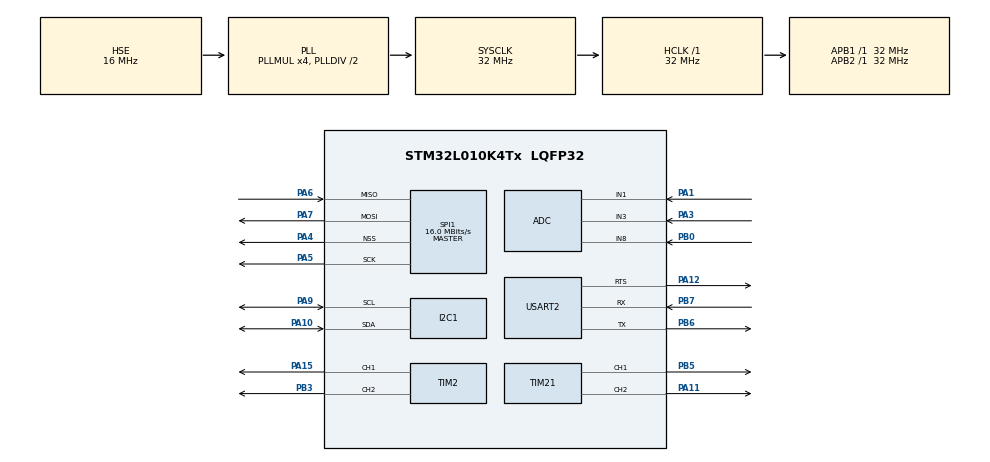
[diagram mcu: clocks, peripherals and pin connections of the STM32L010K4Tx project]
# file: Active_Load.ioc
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Dma.Request0=TIM2_CH1
Dma.Request1=TIM2_CH2
Dma.TIM2_CH1.0.Direction=DMA_MEMORY_TO_PERIPH
Dma.TIM2_CH1.0.Instance=DMA1_Channel5
Dma.TIM2_CH1.0.MemDataAlignment=DMA_MDATAALIGN_HALFWORD
Dma.TIM2_CH1.0.MemInc=DMA_MINC_ENABLE
Dma.TIM2_CH1.0.Mode=DMA_NORMAL
Dma.TIM2_CH1.0.PeriphDataAlignment=DMA_PDATAALIGN_HALFWORD
Dma.TIM2_CH1.0.PeriphInc=DMA_PINC_DISABLE
Dma.TIM2_CH1.0.Priority=DMA_PRIORITY_HIGH
Dma.TIM2_CH2.1.Direction=DMA_MEMORY_TO_PERIPH
Dma.TIM2_CH2.1.Instance=DMA1_Channel3
Dma.TIM2_CH2.1.MemDataAlignment=DMA_MDATAALIGN_HALFWORD
Dma.TIM2_CH2.1.MemInc=DMA_MINC_ENABLE
Dma.TIM2_CH2.1.Mode=DMA_NORMAL
Dma.TIM2_CH2.1.PeriphDataAlignment=DMA_PDATAALIGN_HALFWORD
Dma.TIM2_CH2.1.PeriphInc=DMA_PINC_DISABLE
Dma.TIM2_CH2.1.Priority=DMA_PRIORITY_HIGH
I2C1.Timing=0x00707CBB
Mcu.Family=STM32L0
Mcu.Name=STM32L010K4Tx
Mcu.Package=LQFP32
NVIC.DMA1_Channel2_3_IRQn=true\:0\:0\:false\:false\:true\:false\:true\:true
NVIC.DMA1_Channel4_5_IRQn=true\:0\:0\:false\:false\:true\:false\:true\:true
PA0-CK_IN.Mode=HSE-External-Clock-Source-for-TinyNemo
PA0-CK_IN.Signal=RCC_CK_IN
PA1.Mode=IN1
PA1.Signal=ADC_IN1
PA10.Mode=I2C
PA10.Signal=I2C1_SDA
PA11.Signal=S_TIM21_CH2
PA12.Mode=RTS_Only
PA12.Signal=USART2_RTS
PA13.Mode=Serial_Wire
PA13.Signal=SYS_SWDIO
PA14.Mode=Serial_Wire
PA14.Signal=SYS_SWCLK
PA15.Signal=S_TIM2_CH1
PA2.Mode=SYS_WakeUp2
PA2.Signal=SYS_WKUP3
PA3.Mode=IN3
PA3.Signal=ADC_IN3
PA4.Mode=NSS_Signal_Hard_Output
PA4.Signal=SPI1_NSS
PA5.Mode=Full_Duplex_Master
PA5.Signal=SPI1_SCK
PA6.Mode=Full_Duplex_Master
PA6.Signal=SPI1_MISO
PA7.Mode=Full_Duplex_Master
PA7.Signal=SPI1_MOSI
PA9.Mode=I2C
PA9.Signal=I2C1_SCL
PB0.Mode=IN8
PB0.Signal=ADC_IN8
PB1.Mode=VREFINT_ADC_PB1
PB1.Signal=SYS_VREF_OUT_PB1
PB3.Signal=S_TIM2_CH2
PB5.Signal=S_TIM21_CH1
PB6.Mode=Asynchronous
PB6.Signal=USART2_TX
PB7.Mode=Asynchronous
PB7.Signal=USART2_RX
ProjectManager.HeapSize=0x100
ProjectManager.StackSize=0x200
ProjectManager.TargetToolchain=STM32CubeIDE
RCC.AHBFreq_Value=32000000
RCC.APB1Freq_Value=32000000
RCC.APB1TimFreq_Value=32000000
RCC.APB2Freq_Value=32000000
RCC.APB2TimFreq_Value=32000000
RCC.HCLKFreq_Value=32000000
RCC.HSE_VALUE=16000000
RCC.HSI16_VALUE=16000000
RCC.HSI_VALUE=16000000
RCC.LSE_VALUE=32768
RCC.MSI_VALUE=2097000
RCC.PLLMUL=RCC_PLLMUL_4
RCC.PLLSourceVirtual=RCC_PLLSOURCE_HSE
RCC.SYSCLKFreq_VALUE=32000000
RCC.SYSCLKSource=RCC_SYSCLKSOURCE_PLLCLK
RCC.VCOOutputFreq_Value=64000000
SH.S_TIM21_CH1.0=TIM21_CH1,PWM Generation1 CH1
SH.S_TIM21_CH2.0=TIM21_CH2,PWM Generation2 CH2
SH.S_TIM2_CH1.0=TIM2_CH1,PWM Generation1 CH1
SH.S_TIM2_CH2.0=TIM2_CH2,PWM Generation2 CH2
SPI1.CalculateBaudRate=16.0 MBits/s
SPI1.Direction=SPI_DIRECTION_2LINES
SPI1.Mode=SPI_MODE_MASTER
SPI1.VirtualNSS=VM_NSSHARD
SPI1.VirtualType=VM_MASTER
TIM2.Channel-PWM\ Generation1\ CH1=TIM_CHANNEL_1
TIM2.Channel-PWM\ Generation2\ CH2=TIM_CHANNEL_2
TIM21.Channel-PWM\ Generation1\ CH1=TIM_CHANNEL_1
TIM21.Channel-PWM\ Generation2\ CH2=TIM_CHANNEL_2
USART2.VirtualMode=VM_ASYNC
VP_TIM21_VS_ClockSourceINT.Mode=Internal
VP_TIM2_VS_ClockSourceINT.Mode=Internal
board=custom

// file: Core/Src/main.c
/* USER CODE BEGIN Header */
/**
  ******************************************************************************
  * @file           : main.c
  * @brief          : Main program body
  ******************************************************************************
  * @attention
  *
  * Copyright (c) 2022 STMicroelectronics.
  * All rights reserved.
  *
  * This software is licensed under terms that can be found in the LICENSE file
  * in the root directory of this software component.
  * If no LICENSE file comes with this software, it is provided AS-IS.
  *
  ******************************************************************************
  */
/* USER CODE END Header */
#include "main.h"

/* USER CODE BEGIN Includes */
#include "i2c-lcd.h"
/* USER CODE END Includes */

ADC_HandleTypeDef hadc;

I2C_HandleTypeDef hi2c1;

SPI_HandleTypeDef hspi1;

TIM_HandleTypeDef htim2;
TIM_HandleTypeDef htim21;
DMA_HandleTypeDef hdma_tim2_ch1;
DMA_HandleTypeDef hdma_tim2_ch2;

UART_HandleTypeDef huart2;

void SystemClock_Config(void);
static void MX_GPIO_Init(void);
static void MX_DMA_Init(void);
static void MX_ADC_Init(void);
static void MX_I2C1_Init(void);
static void MX_SPI1_Init(void);
static void MX_TIM2_Init(void);
static void MX_TIM21_Init(void);
static void MX_USART2_UART_Init(void);

int main(void)
{

  /* MCU Configuration--------------------------------------------------------*/

  /* Reset of all peripherals, Initializes the Flash interface and the Systick. */
  HAL_Init();

  /* Configure the system clock */
  SystemClock_Config();

  /* Initialize all configured peripherals */
  MX_GPIO_Init();
  MX_DMA_Init();
  MX_ADC_Init();
  MX_I2C1_Init();
  MX_SPI1_Init();
  MX_TIM2_Init();
  MX_TIM21_Init();
  MX_USART2_UART_Init();
  /* USER CODE BEGIN 2 */

  lcd_init();  //start LCD
  lcd_send_string("cava txt");
  HAL_Delay(5000);
  lcd_clear();
  lcd_put_cur(1,0);
  lcd_send_string("ceva txt22");

  /* USER CODE END 2 */

  /* Infinite loop */
  while (1)
  {

    /* USER CODE BEGIN 3 */

	  // void loop is here
  }
  /* USER CODE END 3 */
}

void SystemClock_Config(void)
{
  RCC_OscInitTypeDef RCC_OscInitStruct = {0};
  RCC_ClkInitTypeDef RCC_ClkInitStruct = {0};
  RCC_PeriphCLKInitTypeDef PeriphClkInit = {0};

  /** Configure the main internal regulator output voltage
  */
  __HAL_PWR_VOLTAGESCALING_CONFIG(PWR_REGULATOR_VOLTAGE_SCALE1);

  /** Initializes the RCC Oscillators according to the specified parameters
  * in the RCC_OscInitTypeDef structure.
  */
  RCC_OscInitStruct.OscillatorType = RCC_OSCILLATORTYPE_HSE;
  RCC_OscInitStruct.HSEState = RCC_HSE_BYPASS;
  RCC_OscInitStruct.PLL.PLLState = RCC_PLL_ON;
  RCC_OscInitStruct.PLL.PLLSource = RCC_PLLSOURCE_HSE;
  RCC_OscInitStruct.PLL.PLLMUL = RCC_PLLMUL_4;
  RCC_OscInitStruct.PLL.PLLDIV = RCC_PLLDIV_2;
  if (HAL_RCC_OscConfig(&RCC_OscInitStruct) != HAL_OK)
  {
    Error_Handler();
  }

  /** Initializes the CPU, AHB and APB buses clocks
  */
  RCC_ClkInitStruct.ClockType = RCC_CLOCKTYPE_HCLK|RCC_CLOCKTYPE_SYSCLK
                              |RCC_CLOCKTYPE_PCLK1|RCC_CLOCKTYPE_PCLK2;
  RCC_ClkInitStruct.SYSCLKSource = RCC_SYSCLKSOURCE_PLLCLK;
  RCC_ClkInitStruct.AHBCLKDivider = RCC_SYSCLK_DIV1;
  RCC_ClkInitStruct.APB1CLKDivider = RCC_HCLK_DIV1;
  RCC_ClkInitStruct.APB2CLKDivider = RCC_HCLK_DIV1;

  if (HAL_RCC_ClockConfig(&RCC_ClkInitStruct, FLASH_LATENCY_1) != HAL_OK)
  {
    Error_Handler();
  }
  PeriphClkInit.PeriphClockSelection = RCC_PERIPHCLK_USART2|RCC_PERIPHCLK_I2C1;
  PeriphClkInit.Usart2ClockSelection = RCC_USART2CLKSOURCE_PCLK1;
  PeriphClkInit.I2c1ClockSelection = RCC_I2C1CLKSOURCE_PCLK1;
  if (HAL_RCCEx_PeriphCLKConfig(&PeriphClkInit) != HAL_OK)
  {
    Error_Handler();
  }
}

static void MX_ADC_Init(void)
{

  ADC_ChannelConfTypeDef sConfig = {0};

  /** Configure the global features of the ADC (Clock, Resolution, Data Alignment and number of conversion)
  */
  hadc.Instance = ADC1;
  hadc.Init.OversamplingMode = DISABLE;
  hadc.Init.ClockPrescaler = ADC_CLOCK_SYNC_PCLK_DIV2;
  hadc.Init.Resolution = ADC_RESOLUTION_12B;
  hadc.Init.SamplingTime = ADC_SAMPLETIME_1CYCLE_5;
  hadc.Init.ScanConvMode = ADC_SCAN_DIRECTION_FORWARD;
  hadc.Init.DataAlign = ADC_DATAALIGN_RIGHT;
  hadc.Init.ContinuousConvMode = DISABLE;
  hadc.Init.DiscontinuousConvMode = DISABLE;
  hadc.Init.ExternalTrigConvEdge = ADC_EXTERNALTRIGCONVEDGE_NONE;
  hadc.Init.ExternalTrigConv = ADC_SOFTWARE_START;
  hadc.Init.DMAContinuousRequests = DISABLE;
  hadc.Init.EOCSelection = ADC_EOC_SINGLE_CONV;
  hadc.Init.Overrun = ADC_OVR_DATA_PRESERVED;
  hadc.Init.LowPowerAutoWait = DISABLE;
  hadc.Init.LowPowerFrequencyMode = DISABLE;
  hadc.Init.LowPowerAutoPowerOff = DISABLE;
  if (HAL_ADC_Init(&hadc) != HAL_OK)
  {
    Error_Handler();
  }

  /** Configure for the selected ADC regular channel to be converted.
  */
  sConfig.Channel = ADC_CHANNEL_1;
  sConfig.Rank = ADC_RANK_CHANNEL_NUMBER;
  if (HAL_ADC_ConfigChannel(&hadc, &sConfig) != HAL_OK)
  {
    Error_Handler();
  }

  /** Configure for the selected ADC regular channel to be converted.
  */
  sConfig.Channel = ADC_CHANNEL_3;
  if (HAL_ADC_ConfigChannel(&hadc, &sConfig) != HAL_OK)
  {
    Error_Handler();
  }

  /** Configure for the selected ADC regular channel to be converted.
  */
  sConfig.Channel = ADC_CHANNEL_8;
  if (HAL_ADC_ConfigChannel(&hadc, &sConfig) != HAL_OK)
  {
    Error_Handler();
  }

}

static void MX_I2C1_Init(void)
{

  hi2c1.Instance = I2C1;
  hi2c1.Init.Timing = 0x00707CBB;
  hi2c1.Init.OwnAddress1 = 0;
  hi2c1.Init.AddressingMode = I2C_ADDRESSINGMODE_7BIT;
  hi2c1.Init.DualAddressMode = I2C_DUALADDRESS_DISABLE;
  hi2c1.Init.OwnAddress2 = 0;
  hi2c1.Init.OwnAddress2Masks = I2C_OA2_NOMASK;
  hi2c1.Init.GeneralCallMode = I2C_GENERALCALL_DISABLE;
  hi2c1.Init.NoStretchMode = I2C_NOSTRETCH_DISABLE;
  if (HAL_I2C_Init(&hi2c1) != HAL_OK)
  {
    Error_Handler();
  }

  /** Configure Analogue filter
  */
  if (HAL_I2CEx_ConfigAnalogFilter(&hi2c1, I2C_ANALOGFILTER_ENABLE) != HAL_OK)
  {
    Error_Handler();
  }

  /** Configure Digital filter
  */
  if (HAL_I2CEx_ConfigDigitalFilter(&hi2c1, 0) != HAL_OK)
  {
    Error_Handler();
  }

}

static void MX_SPI1_Init(void)
{

  /* SPI1 parameter configuration*/
  hspi1.Instance = SPI1;
  hspi1.Init.Mode = SPI_MODE_MASTER;
  hspi1.Init.Direction = SPI_DIRECTION_2LINES;
  hspi1.Init.DataSize = SPI_DATASIZE_8BIT;
  hspi1.Init.CLKPolarity = SPI_POLARITY_LOW;
  hspi1.Init.CLKPhase = SPI_PHASE_1EDGE;
  hspi1.Init.NSS = SPI_NSS_HARD_OUTPUT;
  hspi1.Init.BaudRatePrescaler = SPI_BAUDRATEPRESCALER_2;
  hspi1.Init.FirstBit = SPI_FIRSTBIT_MSB;
  hspi1.Init.TIMode = SPI_TIMODE_DISABLE;
  hspi1.Init.CRCCalculation = SPI_CRCCALCULATION_DISABLE;
  hspi1.Init.CRCPolynomial = 7;
  if (HAL_SPI_Init(&hspi1) != HAL_OK)
  {
    Error_Handler();
  }

}

static void MX_TIM2_Init(void)
{

  TIM_ClockConfigTypeDef sClockSourceConfig = {0};
  TIM_MasterConfigTypeDef sMasterConfig = {0};
  TIM_OC_InitTypeDef sConfigOC = {0};

  htim2.Instance = TIM2;
  htim2.Init.Prescaler = 0;
  htim2.Init.CounterMode = TIM_COUNTERMODE_UP;
  htim2.Init.Period = 65535;
  htim2.Init.ClockDivision = TIM_CLOCKDIVISION_DIV1;
  htim2.Init.AutoReloadPreload = TIM_AUTORELOAD_PRELOAD_DISABLE;
  if (HAL_TIM_Base_Init(&htim2) != HAL_OK)
  {
    Error_Handler();
  }
  sClockSourceConfig.ClockSource = TIM_CLOCKSOURCE_INTERNAL;
  if (HAL_TIM_ConfigClockSource(&htim2, &sClockSourceConfig) != HAL_OK)
  {
    Error_Handler();
  }
  if (HAL_TIM_PWM_Init(&htim2) != HAL_OK)
  {
    Error_Handler();
  }
  sMasterConfig.MasterOutputTrigger = TIM_TRGO_RESET;
  sMasterConfig.MasterSlaveMode = TIM_MASTERSLAVEMODE_DISABLE;
  if (HAL_TIMEx_MasterConfigSynchronization(&htim2, &sMasterConfig) != HAL_OK)
  {
    Error_Handler();
  }
  sConfigOC.OCMode = TIM_OCMODE_PWM1;
  sConfigOC.Pulse = 0;
  sConfigOC.OCPolarity = TIM_OCPOLARITY_HIGH;
  sConfigOC.OCFastMode = TIM_OCFAST_DISABLE;
  if (HAL_TIM_PWM_ConfigChannel(&htim2, &sConfigOC, TIM_CHANNEL_1) != HAL_OK)
  {
    Error_Handler();
  }
  if (HAL_TIM_PWM_ConfigChannel(&htim2, &sConfigOC, TIM_CHANNEL_2) != HAL_OK)
  {
    Error_Handler();
  }
  HAL_TIM_MspPostInit(&htim2);

}

static void MX_TIM21_Init(void)
{

  TIM_ClockConfigTypeDef sClockSourceConfig = {0};
  TIM_MasterConfigTypeDef sMasterConfig = {0};
  TIM_OC_InitTypeDef sConfigOC = {0};

  htim21.Instance = TIM21;
  htim21.Init.Prescaler = 0;
  htim21.Init.CounterMode = TIM_COUNTERMODE_UP;
  htim21.Init.Period = 65535;
  htim21.Init.ClockDivision = TIM_CLOCKDIVISION_DIV1;
  htim21.Init.AutoReloadPreload = TIM_AUTORELOAD_PRELOAD_DISABLE;
  if (HAL_TIM_Base_Init(&htim21) != HAL_OK)
  {
    Error_Handler();
  }
  sClockSourceConfig.ClockSource = TIM_CLOCKSOURCE_INTERNAL;
  if (HAL_TIM_ConfigClockSource(&htim21, &sClockSourceConfig) != HAL_OK)
  {
    Error_Handler();
  }
  if (HAL_TIM_PWM_Init(&htim21) != HAL_OK)
  {
    Error_Handler();
  }
  sMasterConfig.MasterOutputTrigger = TIM_TRGO_RESET;
  sMasterConfig.MasterSlaveMode = TIM_MASTERSLAVEMODE_DISABLE;
  if (HAL_TIMEx_MasterConfigSynchronization(&htim21, &sMasterConfig) != HAL_OK)
  {
    Error_Handler();
  }
  sConfigOC.OCMode = TIM_OCMODE_PWM1;
  sConfigOC.Pulse = 0;
  sConfigOC.OCPolarity = TIM_OCPOLARITY_HIGH;
  sConfigOC.OCFastMode = TIM_OCFAST_DISABLE;
  if (HAL_TIM_PWM_ConfigChannel(&htim21, &sConfigOC, TIM_CHANNEL_1) != HAL_OK)
  {
    Error_Handler();
  }
  if (HAL_TIM_PWM_ConfigChannel(&htim21, &sConfigOC, TIM_CHANNEL_2) != HAL_OK)
  {
    Error_Handler();
  }
  HAL_TIM_MspPostInit(&htim21);

}

static void MX_USART2_UART_Init(void)
{

  huart2.Instance = USART2;
  huart2.Init.BaudRate = 115200;
  huart2.Init.WordLength = UART_WORDLENGTH_8B;
  huart2.Init.StopBits = UART_STOPBITS_1;
  huart2.Init.Parity = UART_PARITY_NONE;
  huart2.Init.Mode = UART_MODE_TX_RX;
  huart2.Init.HwFlowCtl = UART_HWCONTROL_RTS;
  huart2.Init.OverSampling = UART_OVERSAMPLING_16;
  huart2.Init.OneBitSampling = UART_ONE_BIT_SAMPLE_DISABLE;
  huart2.AdvancedInit.AdvFeatureInit = UART_ADVFEATURE_NO_INIT;
  if (HAL_UART_Init(&huart2) != HAL_OK)
  {
    Error_Handler();
  }

}

static void MX_DMA_Init(void)
{

  /* DMA controller clock enable */
  __HAL_RCC_DMA1_CLK_ENABLE();

  /* DMA interrupt init */
  /* DMA1_Channel2_3_IRQn interrupt configuration */
  HAL_NVIC_SetPriority(DMA1_Channel2_3_IRQn, 0, 0);
  HAL_NVIC_EnableIRQ(DMA1_Channel2_3_IRQn);
  /* DMA1_Channel4_5_IRQn interrupt configuration */
  HAL_NVIC_SetPriority(DMA1_Channel4_5_IRQn, 0, 0);
  HAL_NVIC_EnableIRQ(DMA1_Channel4_5_IRQn);

}

static void MX_GPIO_Init(void)
{
  GPIO_InitTypeDef GPIO_InitStruct = {0};

  /* GPIO Ports Clock Enable */
  __HAL_RCC_GPIOA_CLK_ENABLE();
  __HAL_RCC_GPIOB_CLK_ENABLE();

  /*Configure GPIO pin : PB1 */
  GPIO_InitStruct.Pin = GPIO_PIN_1;
  GPIO_InitStruct.Mode = GPIO_MODE_ANALOG;
  GPIO_InitStruct.Pull = GPIO_NOPULL;
  HAL_GPIO_Init(GPIOB, &GPIO_InitStruct);

}

void Error_Handler(void)
{
  __disable_irq();
  while (1)
  {
  }
}
